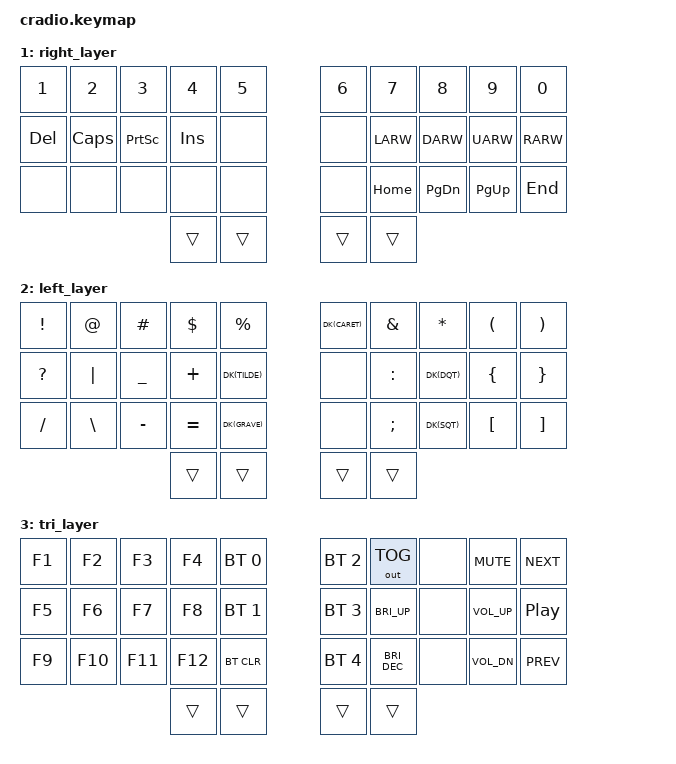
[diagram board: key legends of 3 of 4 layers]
// Copyright (c) 2022 The ZMK Contributors
// SPDX-License-Identifier: MIT

#include <behaviors.dtsi>
#include <dt-bindings/zmk/keys.h>
#include <dt-bindings/zmk/bt.h>
#include <dt-bindings/zmk/outputs.h>

// Home row mods macro
#define HRML(k1,k2,k3) &ht LCTRL k1  &ht LGUI k2  &ht LALT k3
#define HRMR(k1,k2,k3) &ht RALT k1  &ht RGUI k2  &ht RCTRL k3
#define DK(k1) &dkht k1 k1

#define OE RA(P)
#define UE RA(Y)
#define AE RA(Q)

#define WIN 0
#define RIG 1
#define LEF 2
#define TRI 3

/ {
    macros {
        w_spc: with_space_macro {
            compatible = "zmk,behavior-macro-one-param";
            wait-ms = <30>;
            tap-ms = <30>;
            #binding-cells = <1>;
            bindings = <&macro_param_1to1>, <&kp MACRO_PLACEHOLDER>, <&kp SPACE>;
        };
    };

    behaviors {
        ht: hold_tap {
            label = "hold_tap";
            compatible = "zmk,behavior-hold-tap";
            #binding-cells = <2>;
            flavor = "tap-preferred";
            tapping-term-ms = <220>;
            quick-tap-ms = <150>;
            global-quick-tap;
            bindings = <&kp>, <&kp>;
        };

        dkht: dead_key_hold_tap {
            label = "dead_key_space";
            compatible = "zmk,behavior-hold-tap";
            #binding-cells = <2>;
            flavor = "tap-preferred";
            tapping-term-ms = <220>;
            quick-tap-ms = <150>;
            global-quick-tap;
            bindings = <&kp>, <&w_spc>;
        };
    };

    conditional_layers {
        compatible = "zmk,conditional-layers";
        tri_layer {
            if-layers = <RIG LEF>;
            then-layer = <TRI>;
        };
    };

    keymap {
        compatible = "zmk,keymap";
        default_layer {
            bindings = <
        //╭──────────┬──────────┬──────────┬──────────┬──────────╮   ╭──────────┬──────────┬──────────┬──────────┬──────────╮
        //│ Q        │ W        │ E        │ R        │ T        │   │ Y        │ U        │ I        │ O        │ P        │
            &kp Q      &kp W      &kp E      &kp R      &kp T          &kp Y      &mt UE U   &kp I     &mt OE O    &kp P
        //├──────────┼──────────┼──────────┼──────────┼──────────┤   ├──────────┼──────────┼──────────┼──────────┼──────────┤
        //│ A        │ S (CTRL) │ D (WIN)  │ F (ALT)  │ G        │   │ H        │ J (ALT)  │ K (WIN)  │ L (CTRL) │ BACKSPACE│
           &mt AE A    HRML(S,    D,         F)         &kp G          &kp H      HRMR(J,    K,         L)         &kp BSPC
        //├──────────┼──────────┼──────────┼──────────┼──────────┤   ├──────────┼──────────┼──────────┼──────────┼──────────┤
        //│ Z        │ X        │ C        │ V        │ B        │   │ N        │ M        │ , (<)    │ . (>)    │ ENTER    │
            &kp Z      &kp X      &kp C      &kp V      &kp B          &kp N      &kp M      &kp COMMA  &kp DOT    &kp ENTER
        //╰──────────┴──────────┴──────────┼──────────┼──────────┤   ├──────────┼──────────┼──────────┴──────────┴──────────╯
                                           &lt LEF TAB  &kp LSHIFT     &kp SPACE  &lt RIG ESC
        //                                 ╰──────────┴──────────╯   ╰──────────┴──────────╯
            >;
        };

        right_layer {
            bindings = <
        //╭──────────┬──────────┬──────────┬──────────┬──────────╮   ╭──────────┬──────────┬──────────┬──────────┬──────────╮
        //│ 1        │ 2        │ 3        │ 4        │ 5        │   │ 6        │ 7        │ 8        │ 9        │ 0        │
            &kp N1     &kp N2     &kp N3     &kp N4     &kp N5         &kp N6     &kp N7     &kp N8     &kp N9      &kp N0
        //├──────────┼──────────┼──────────┼──────────┼──────────┤   ├──────────┼──────────┼──────────┼──────────┼──────────┤
        //│ DELETE   │ CapsLock │ PrintSc  │ INSERT   │          |   |          │ LEFT     │ DOWN     │ UP       │ RIGHT    │
            &kp DEL    &kp CAPS   &kp PSCRN  &kp INS    &none          &none      &kp LARW   &kp DARW   &kp UARW   &kp RARW 
        //├──────────┼──────────┼──────────┼──────────┼──────────┤   ├──────────┼──────────┼──────────┼──────────┼──────────┤
        //│          │          │          │          │          │   │          │ HOME     │ PAGE DN  │ PAGE UP  │ END      │
            &none      &none      &none      &none      &none          &none      &kp HOME   &kp PG_DN  &kp PG_UP  &kp END 
        //╰──────────┴──────────┴──────────┼──────────┼──────────┤   ├──────────┼──────────┼──────────┴──────────┴──────────╯
                                             &trans     &trans      &trans     &trans
        //                                 ╰──────────┴──────────╯   ╰──────────┴──────────╯
            >;
        };

        left_layer {
            bindings = <
        //╭──────────┬──────────┬──────────┬──────────┬──────────╮   ╭──────────┬──────────┬──────────┬──────────┬──────────╮
        //│ !        │ @        │ #        │ $        │ %        │   │ ^ (^+)   │ &        │ *        │ (        │ )        │
            &kp EXCL   &kp AT     &kp HASH   &kp DLLR   &kp PRCNT     DK(CARET)   &kp AMPS   &kp ASTRK  &kp LPAR   &kp RPAR 
        //├──────────┼──────────┼──────────┼──────────┼──────────┤   ├──────────┼──────────┼──────────┼──────────┼──────────┤
        //│ ?        │ │        │ _        │ +        │ ~ (~+)   │   │          │ :        │ " ("+)   │ {        │ }        │
            &kp QMARK  &kp PIPE   &kp UNDER  &kp PLUS   DK(TILDE)      &none      &kp COLON  DK(DQT)    &kp LBRC   &kp RBRC 
        //├──────────┼──────────┼──────────┼──────────┼──────────┤   ├──────────┼──────────┼──────────┼──────────┼──────────┤
        //│ /        │ \        │ -        │ =        │ ` (`+)   │   │          │ ;        │ ' ('+)   │ [        │ ]        │
            &kp FSLH   &kp BSLH   &kp MINUS  &kp EQUAL  DK(GRAVE)      &none      &kp SEMI   DK(SQT)    &kp LBKT   &kp RBKT 
        //╰──────────┴──────────┴──────────┼──────────┼──────────┤   ├──────────┼──────────┼──────────┴──────────┴──────────╯
                                             &trans     &trans         &trans     &trans
        //                                 ╰──────────┴──────────╯   ╰──────────┴──────────╯
            >;
        };

        tri_layer {
            bindings = <
        //╭──────────┬──────────┬──────────┬───────────┬────────────╮   ╭────────────┬────────────┬──────────┬───────────┬──────────╮
        //│ F1       │ F2       │ F3       │ F4        │ PROFILE 0  │   │ PROFILE 2  │ TOGGLEOUT  │          │ VOL MUTE  │ NEXTSONG │
            &kp F1     &kp F2     &kp F3     &kp F4     &bt BT_SEL 0     &bt BT_SEL 2  &out OUT_TOG &none      &kp C_MUTE  &kp C_NEXT
        //├──────────┼──────────┼──────────┼───────────┼────────────┤   ├────────────┼────────────┼──────────┼───────────┼──────────┤
        //│ F5       │ F6       │ F7       │ F8        │ PROFILE 1  │   │ PROFILE 3  │ INC BRIGHT │          │ VOL UP    │PAUSEMUSIC│
            &kp F5     &kp F6     &kp F7     &kp F8     &bt BT_SEL 1     &bt BT_SEL 3  &kp C_BRI_UP &none     &kp C_VOL_UP &kp C_PP
        //├──────────┼──────────┼──────────┼───────────┼────────────┤   ├────────────┼────────────┼──────────┼───────────┼──────────┤
        //│ F9       │ F10      │ F11      │ F12       │ CLEAR BT   │   │ PROFILE 4  │ DEC BRIGHT │          | VOL DOWN  │ PREVSONG │
            &kp F9     &kp F10    &kp F11    &kp F12     &bt BT_CLR      &bt BT_SEL 4  &kp C_BRI_DEC &none    &kp C_VOL_DN &kp C_PREV
        //╰──────────┴──────────┴──────────┼───────────┼────────────┤   ├────────────┼────────────┼──────────┴───────────┴──────────╯
                                             &trans      &trans           &trans       &trans
        //                                 ╰───────────┴────────────╯   ╰────────────┴────────────╯
            >;
        };
    };
};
